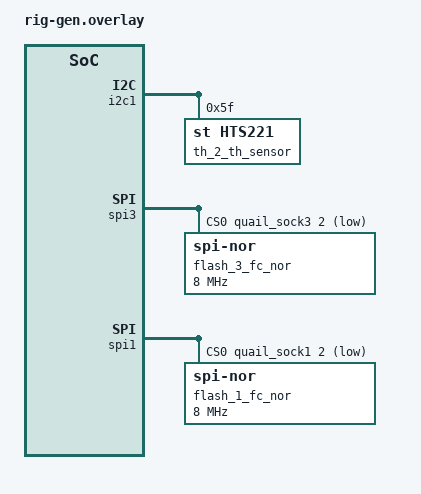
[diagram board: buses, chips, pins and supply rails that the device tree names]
/* generated by rigc — do not edit; the rig file is the source of truth
 * rig: quail_sockets  board: mikroe_quail/stm32f427xx/rig
 */

&i2c1 {
	th_2_th_sensor: sensor@5f {
		compatible = "st,hts221";
		reg = <0x5f>;
		status = "okay";
	};
};

&spi3 {
	cs-gpios = <&quail_sock3 2 1 /* ACTIVE_LOW */>;
	flash_3_fc_nor: nor@0 {
		compatible = "jedec,spi-nor";
		spi-max-frequency = <8000000>;
		jedec-id = [c8 40 15];
		size = <4194304>;
		reg = <0>;
		status = "okay";
	};
};

&spi1 {
	cs-gpios = <&quail_sock1 2 1 /* ACTIVE_LOW */>;
	flash_1_fc_nor: nor@0 {
		compatible = "jedec,spi-nor";
		spi-max-frequency = <8000000>;
		jedec-id = [c8 40 15];
		size = <4194304>;
		reg = <0>;
		status = "okay";
	};
};
